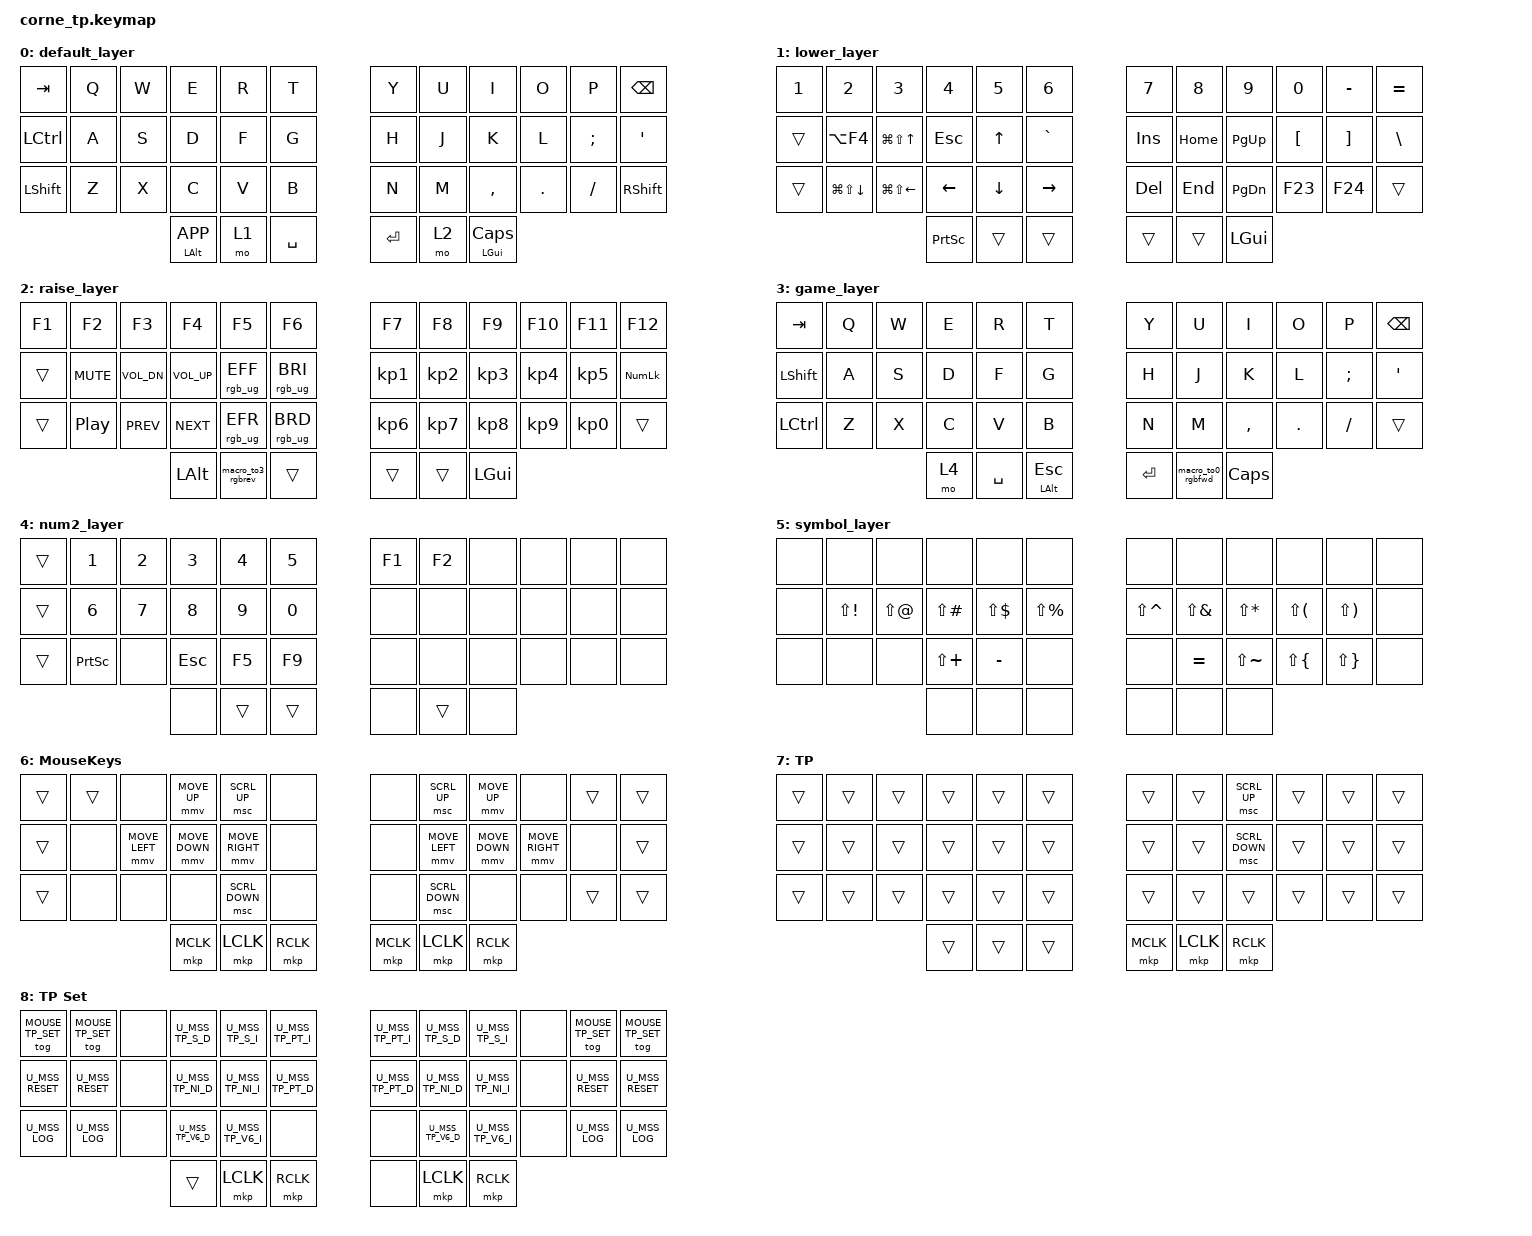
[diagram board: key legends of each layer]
/*
 * Автоматически сконвертировано из Vial (.vil) в ZMK.
 * Проверьте раскладку перед прошивкой!
 */

#include <dt-bindings/zmk/mouse.h>
#include <behaviors.dtsi>
#include <dt-bindings/zmk/keys.h>
#include <dt-bindings/zmk/rgb.h>

#define MOUSE_KEYS 6
#define MOUSE_TP 7
#define MOUSE_TP_SET 8

#define HAS_MOUSE_KEYS
#define HAS_MOUSE_TP

#ifdef HAS_MOUSE_KEYS
  #include <dt-bindings/zmk/mouse.h>
  #include <behaviors/mouse_keys.dtsi>
#endif  // HAS_MOUSE_KEYS

#ifdef HAS_MOUSE_TP
  // We store the trackpoint settings in a separate file
  // to make organization a little easier.
  #include "include/mouse_tp.dtsi"
#endif  // HAS_MOUSE_TP

// Adjust layer keys based on enabled features.
//
// This prevents build errors when we build the firmware
// without the mouse keys PR or the TP module.
#ifdef HAS_MOUSE_KEYS
  #define U_THUMB_INNER &mo MOUSE_KEYS
#else
  #define U_THUMB_INNER &none
#endif  // HAS_MOUSE_KEYS

#ifdef HAS_MOUSE_TP
  #define U_TOG_TP_SET &tog MOUSE_TP_SET
#else
  #define U_TOG_TP_SET &none
#endif  // HAS_MOUSE_TP

/ {
    behaviors {
        // Home row mod для ЛЕВОЙ руки: срабатывает как модификатор только
        // если параллельно нажата клавиша ПРАВОЙ руки (positional hold-tap).
        // Это убирает случайные срабатывания при быстром наборе одной рукой.
        // Зеркальный home row mod для ПРАВОЙ руки.
    };

    macros {
        macro_to3_rgbrev: macro_to3_rgbrev {
            compatible = "zmk,behavior-macro";
            #binding-cells = <0>;
            bindings = <&to 3 &rgb_ug RGB_EFR>;
        };

        macro_to0_rgbfwd: macro_to0_rgbfwd {
            compatible = "zmk,behavior-macro";
            #binding-cells = <0>;
            bindings = <&rgb_ug RGB_EFF &to 0>;
        };
    };

    combos {
        compatible = "zmk,combos";

        left-shift {
            bindings = <&kp LEFT_SHIFT>;
            key-positions = <15 14>;
            require-prior-idle-ms = <150>;
            layers = <0 1 2>;
        };

        right-shift {
            bindings = <&kp RSHIFT>;
            key-positions = <20 21>;
            require-prior-idle-ms = <150>;
            layers = <0 1 2>;
        };

        symbols-right {
            bindings = <&mo 5>;
            key-positions = <20 19>;
            layers = <0>;
        };

        symbols-left {
            bindings = <&mo 5>;
            key-positions = <15 16>;
            layers = <0>;
        };
    };

    keymap {
        compatible = "zmk,keymap";

        default_layer {
            bindings = <
&kp TAB    &kp Q  &kp W  &kp E           &kp R  &kp T        &kp Y    &kp U  &kp I          &kp O    &kp P     &kp BSPC
&kp LCTRL  &kp A  &kp S  &kp D           &kp F  &kp G        &kp H    &kp J  &kp K          &kp L    &kp SEMI  &kp SQT
&kp LSHFT  &kp Z  &kp X  &kp C           &kp V  &kp B        &kp N    &kp M  &kp COMMA      &kp DOT  &kp FSLH  &kp RSHFT
                         &mt LALT K_APP  &mo 1  &kp SPACE    &kp RET  &mo 2  &mt LGUI CAPS
            >;
        };

        lower_layer {
            bindings = <
&kp N1  &kp N2            &kp N3            &kp N4     &kp N5    &kp N6       &kp N7   &kp N8    &kp N9     &kp N0    &kp MINUS  &kp EQUAL
&trans  &kp LA(F4)        &kp LG(LS(UP))    &kp ESC    &kp UP    &kp GRAVE    &kp INS  &kp HOME  &kp PG_UP  &kp LBKT  &kp RBKT   &kp BSLH
&trans  &kp LG(LS(DOWN))  &kp LG(LS(LEFT))  &kp LEFT   &kp DOWN  &kp RIGHT    &kp DEL  &kp END   &kp PG_DN  &kp F23   &kp F24    &trans
                                            &kp PSCRN  &trans    &trans       &trans   &trans    &kp LGUI
            >;
        };

        raise_layer {
            bindings = <
&kp F1  &kp F2      &kp F3        &kp F4        &kp F5             &kp F6             &kp F7     &kp F8     &kp F9     &kp F10    &kp F11    &kp F12
&trans  &kp C_MUTE  &kp C_VOL_DN  &kp C_VOL_UP  &rgb_ug RGB_EFF    &rgb_ug RGB_BRI    &kp KP_N1  &kp KP_N2  &kp KP_N3  &kp KP_N4  &kp KP_N5  &kp KP_NUM
&trans  &kp C_PP    &kp C_PREV    &kp C_NEXT    &rgb_ug RGB_EFR    &rgb_ug RGB_BRD    &kp KP_N6  &kp KP_N7  &kp KP_N8  &kp KP_N9  &kp KP_N0  &trans
                                  &kp LALT      &macro_to3_rgbrev  &trans             &trans     &trans     &kp LGUI
            >;
        };

        game_layer {
            bindings = <
&kp TAB    &kp Q  &kp W  &kp E  &kp R      &kp T               &kp Y    &kp U              &kp I      &kp O    &kp P     &kp BSPC
&kp LSHFT  &kp A  &kp S  &kp D  &kp F      &kp G               &kp H    &kp J              &kp K      &kp L    &kp SEMI  &kp SQT
&kp LCTRL  &kp Z  &kp X  &kp C  &kp V      &kp B               &kp N    &kp M              &kp COMMA  &kp DOT  &kp FSLH  &trans
                         &mo 4  &kp SPACE  &mt LEFT_ALT ESC    &kp RET  &macro_to0_rgbfwd  &kp CAPS
            >;
        };

        num2_layer {
            bindings = <
&trans  &kp N1     &kp N2  &kp N3      &kp N4  &kp N5    &kp F1  &kp F2  &none  &none  &none  &none
&trans  &kp N6     &kp N7  &kp N8      &kp N9  &kp N0    &none   &none   &none  &none  &none  &none
&trans  &kp PSCRN  &none   &kp ESCAPE  &kp F5  &kp F9    &none   &none   &none  &none  &none  &none
                           &none       &trans  &trans    &none   &trans  &none
            >;
        };

        symbol_layer {
            bindings = <
&none  &none         &none       &none          &none         &none            &none          &none         &none          &none         &none         &none
&none  &kp LS(EXCL)  &kp LS(AT)  &kp LS(POUND)  &kp LS(DLLR)  &kp LS(PRCNT)    &kp LS(CARET)  &kp LS(AMPS)  &kp LS(STAR)   &kp LS(LPAR)  &kp LS(RPAR)  &none
&none  &none         &none       &kp LS(PLUS)   &kp MINUS     &none            &none          &kp EQUAL     &kp LS(TILDE)  &kp LS(LBRC)  &kp LS(RBRC)  &none
                                 &none          &none         &none            &none          &none         &none
            >;
        };

        #ifdef HAS_MOUSE_KEYS

    MouseKeys_layer {
      display-name = "MouseKeys";
      bindings = <
// ╭────────────────────────┬────────────────────────┬────────────────────────┬────────────────────────┬────────────────────────┬────────────────────────╮    ╭────────────────────────┬────────────────────────┬────────────────────────┬────────────────────────┬────────────────────────┬────────────────────────╮
     &trans                   &trans                   &none                    &mmv MOVE_UP             &msc SCRL_UP             &none                         &none                    &msc SCRL_UP             &mmv MOVE_UP             &none                    &trans                    &trans
// ├────────────────────────┼────────────────────────┼────────────────────────┼────────────────────────┼────────────────────────┼────────────────────────┤    ├────────────────────────┼────────────────────────┼────────────────────────┼────────────────────────┼────────────────────────┼────────────────────────┤
     &trans                   &none                    &mmv MOVE_LEFT           &mmv MOVE_DOWN           &mmv MOVE_RIGHT          &none                         &none                    &mmv MOVE_LEFT           &mmv MOVE_DOWN           &mmv MOVE_RIGHT          &none                     &trans
// ├────────────────────────┼────────────────────────┼────────────────────────┼────────────────────────┼────────────────────────┼────────────────────────┤    ├────────────────────────┼────────────────────────┼────────────────────────┼────────────────────────┼────────────────────────┼────────────────────────┤
     &trans                   &none                    &none                    &none                    &msc SCRL_DOWN           &none                         &none                    &msc SCRL_DOWN           &none                    &none                    &trans                    &trans
// ╰────────────────────────┴────────────────────────┴────────────────────────┴────────────────────────┼────────────────────────┼────────────────────────┤    ├────────────────────────┼────────────────────────┼────────────────────────┼────────────────────────┴────────────────────────┼────────────────────────╯
                                                                                &mkp MCLK                &mkp LCLK                &mkp RCLK                     &mkp MCLK                &mkp LCLK                &mkp RCLK
//                                                                            ╰────────────────────────┴────────────────────────┴────────────────────────╯    ╰────────────────────────┴────────────────────────┴────────────────────────╯
      >;
    };

#endif

#ifdef HAS_MOUSE_TP

    // Automatically activated when the mouse or trackpoint moves.
    // Configured in `include/mouse_tp.dtsi`.
    MouseTP_layer {
      display-name = "TP";
      bindings = <
// Прокрутка: I (вверх) и K (вниз). Кнопки мыши - только правая половина.
// Переключения на слой TP Set нет.
     &trans  &trans  &trans  &trans  &trans  &trans      &trans  &trans  &msc SCRL_UP    &trans  &trans  &trans
     &trans  &trans  &trans  &trans  &trans  &trans      &trans  &trans  &msc SCRL_DOWN  &trans  &trans  &trans
     &trans  &trans  &trans  &trans  &trans  &trans      &trans  &trans  &trans          &trans  &trans  &trans
                             &trans  &trans  &trans      &mkp MCLK  &mkp LCLK  &mkp RCLK
      >;
    };

    // You can find the defines for the actual key press behaviors in `include/mouse_tp.dtsi`.
    MouseSettings_layer {
      display-name = "TP Set";
      bindings = <
// ╭────────────────────────┬────────────────────────┬────────────────────────┬────────────────────────┬────────────────────────┬────────────────────────╮    ╭────────────────────────┬────────────────────────┬────────────────────────┬────────────────────────┬────────────────────────┬────────────────────────╮
     U_TOG_TP_SET             U_TOG_TP_SET             &none                    U_MSS_TP_S_D             U_MSS_TP_S_I             U_MSS_TP_PT_I                 U_MSS_TP_PT_I            U_MSS_TP_S_D             U_MSS_TP_S_I             &none                    U_TOG_TP_SET              U_TOG_TP_SET
// ├────────────────────────┼────────────────────────┼────────────────────────┼────────────────────────┼────────────────────────┼────────────────────────┤    ├────────────────────────┼────────────────────────┼────────────────────────┼────────────────────────┼────────────────────────┼────────────────────────┤
     U_MSS_RESET              U_MSS_RESET              &none                    U_MSS_TP_NI_D            U_MSS_TP_NI_I            U_MSS_TP_PT_D                 U_MSS_TP_PT_D            U_MSS_TP_NI_D            U_MSS_TP_NI_I            &none                    U_MSS_RESET               U_MSS_RESET
// ├────────────────────────┼────────────────────────┼────────────────────────┼────────────────────────┼────────────────────────┼────────────────────────┤    ├────────────────────────┼────────────────────────┼────────────────────────┼────────────────────────┼────────────────────────┼────────────────────────┤
     U_MSS_LOG                U_MSS_LOG                &none                    U_MSS_TP_V6_D            U_MSS_TP_V6_I            &none                         &none                    U_MSS_TP_V6_D            U_MSS_TP_V6_I            &none                    U_MSS_LOG                 U_MSS_LOG
// ╰────────────────────────┴────────────────────────┴────────────────────────┴────────────────────────┼────────────────────────┼────────────────────────┤    ├────────────────────────┼────────────────────────┼────────────────────────┼────────────────────────┴────────────────────────┼────────────────────────╯
                                                                                &trans                   &mkp LCLK                &mkp RCLK                     &none                    &mkp LCLK                &mkp RCLK
//                                                                            ╰────────────────────────┴────────────────────────┴────────────────────────╯    ╰────────────────────────┴────────────────────────┴────────────────────────╯
      >;
    };

#endif
    };
};
